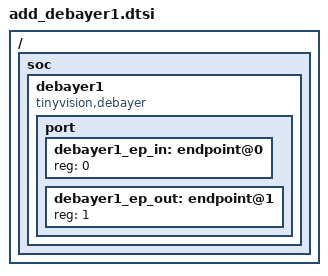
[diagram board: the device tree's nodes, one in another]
/*
 * Copyright (c) 2024-2025 tinyVision.ai Inc.
 *
 * SPDX-License-Identifier: Apache-2.0
 */

/ {
	soc {
		debayer1: debayer1 {
			compatible = "tinyvision,debayer";

			port {
				#address-cells = <1>;
				#size-cells = <0>;

				debayer1_ep_in: endpoint@0 {
					reg = <0>;
				};

				debayer1_ep_out: endpoint@1 {
					reg = <1>;
				};
			};
		};
	};
};
